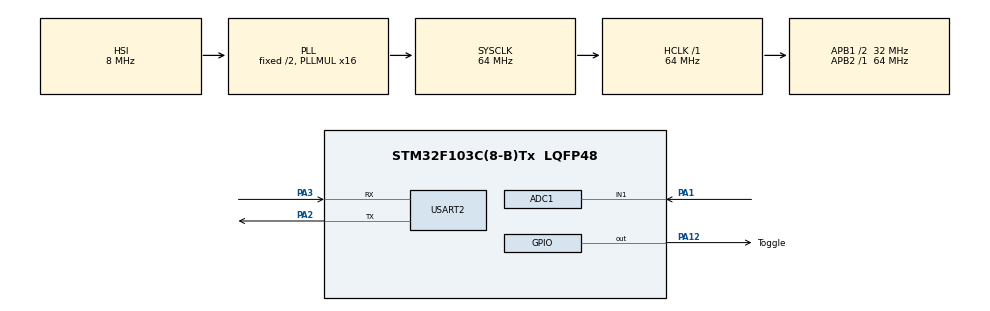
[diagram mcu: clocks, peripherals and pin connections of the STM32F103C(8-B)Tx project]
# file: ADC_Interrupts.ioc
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ADC1.Channel-0\#ChannelRegularConversion=ADC_CHANNEL_1
ADC1.ContinuousConvMode=ENABLE
ADC1.EnableAnalogWatchDog=false
ADC1.InjNumberOfConversion=0
ADC1.NbrOfConversion=1
ADC1.NbrOfConversionFlag=1
ADC1.Rank-0\#ChannelRegularConversion=1
ADC1.SamplingTime-0\#ChannelRegularConversion=ADC_SAMPLETIME_1CYCLE_5
ADC1.master=1
Mcu.Family=STM32F1
Mcu.Name=STM32F103C(8-B)Tx
Mcu.Package=LQFP48
NVIC.ADC1_2_IRQn=true\:0\:0\:false\:false\:true\:true\:true
NVIC.PriorityGroup=NVIC_PRIORITYGROUP_4
PA1.Signal=ADCx_IN1
PA12.GPIO_Label=Toggle
PA12.Signal=GPIO_Output
PA2.Mode=Asynchronous
PA2.Signal=USART2_TX
PA3.Mode=Asynchronous
PA3.Signal=USART2_RX
ProjectManager.HeapSize=0x200
ProjectManager.StackSize=0x400
ProjectManager.TargetToolchain=STM32CubeIDE
RCC.ADCPresc=RCC_ADCPCLK2_DIV6
RCC.AHBFreq_Value=64000000
RCC.APB1CLKDivider=RCC_HCLK_DIV2
RCC.APB1Freq_Value=32000000
RCC.APB1TimFreq_Value=64000000
RCC.APB2Freq_Value=64000000
RCC.APB2TimFreq_Value=64000000
RCC.HCLKFreq_Value=64000000
RCC.PLLMUL=RCC_PLL_MUL16
RCC.SYSCLKFreq_VALUE=64000000
RCC.SYSCLKSource=RCC_SYSCLKSOURCE_PLLCLK
RCC.USBFreq_Value=64000000
SH.ADCx_IN1.0=ADC1_IN1,IN1
USART2.Parity=PARITY_NONE
USART2.VirtualMode=VM_ASYNC
VP_SYS_VS_ND.Mode=No_Debug
board=custom

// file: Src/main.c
/* USER CODE BEGIN Header */
/**
  ******************************************************************************
  * @file           : main.c
  * @brief          : Main program body
  ******************************************************************************
  * @attention
  *
  * <h2><center>&copy; Copyright (c) 2019 STMicroelectronics.
  * All rights reserved.</center></h2>
  *
  * This software component is licensed by ST under BSD 3-Clause license,
  * the "License"; You may not use this file except in compliance with the
  * License. You may obtain a copy of the License at:
  *                        opensource.org/licenses/BSD-3-Clause
  *
  ******************************************************************************
  */
/* USER CODE END Header */

#include "main.h"

ADC_HandleTypeDef hadc1;

UART_HandleTypeDef huart2;

void SystemClock_Config(void);
static void MX_GPIO_Init(void);
static void MX_ADC1_Init(void);
static void MX_USART2_UART_Init(void);

int main(void)
{

  /* MCU Configuration--------------------------------------------------------*/

  /* Reset of all peripherals, Initializes the Flash interface and the Systick. */
  HAL_Init();

  /* Configure the system clock */
  SystemClock_Config();

  /* Initialize all configured peripherals */
  MX_GPIO_Init();
  MX_ADC1_Init();
  MX_USART2_UART_Init();
  /* USER CODE BEGIN 2 */

  HAL_UART_Transmit(&huart2, (uint8_t*) "begin\r\n", 7, HAL_MAX_DELAY);

  HAL_NVIC_SetPriority(ADC1_IRQn, 0, 0);
  HAL_NVIC_EnableIRQ(ADC1_IRQn);

  char msg[10];

  uint16_t aux = HAL_ADC_Start_IT(&hadc1);
  sprintf(msg, "%d\r\n", aux);
  HAL_UART_Transmit(&huart2, (uint8_t*) msg, 7, HAL_MAX_DELAY);
  /* USER CODE END 2 */

  /* Infinite loop */
  /* USER CODE BEGIN WHILE */
  while (1)
  {

	  //HAL_Delay(500);
	  //HAL_UART_Transmit(&huart2, (uint8_t*) "While Loop\r\n", 12, HAL_MAX_DELAY);

    /* USER CODE END WHILE */

  }
}

void SystemClock_Config(void)
{
  RCC_OscInitTypeDef RCC_OscInitStruct = {0};
  RCC_ClkInitTypeDef RCC_ClkInitStruct = {0};
  RCC_PeriphCLKInitTypeDef PeriphClkInit = {0};

  /** Initializes the CPU, AHB and APB busses clocks
  */
  RCC_OscInitStruct.OscillatorType = RCC_OSCILLATORTYPE_HSI;
  RCC_OscInitStruct.HSIState = RCC_HSI_ON;
  RCC_OscInitStruct.HSICalibrationValue = RCC_HSICALIBRATION_DEFAULT;
  RCC_OscInitStruct.PLL.PLLState = RCC_PLL_ON;
  RCC_OscInitStruct.PLL.PLLSource = RCC_PLLSOURCE_HSI_DIV2;
  RCC_OscInitStruct.PLL.PLLMUL = RCC_PLL_MUL16;
  if (HAL_RCC_OscConfig(&RCC_OscInitStruct) != HAL_OK)
  {
    Error_Handler();
  }
  /** Initializes the CPU, AHB and APB busses clocks
  */
  RCC_ClkInitStruct.ClockType = RCC_CLOCKTYPE_HCLK|RCC_CLOCKTYPE_SYSCLK
                              |RCC_CLOCKTYPE_PCLK1|RCC_CLOCKTYPE_PCLK2;
  RCC_ClkInitStruct.SYSCLKSource = RCC_SYSCLKSOURCE_PLLCLK;
  RCC_ClkInitStruct.AHBCLKDivider = RCC_SYSCLK_DIV1;
  RCC_ClkInitStruct.APB1CLKDivider = RCC_HCLK_DIV2;
  RCC_ClkInitStruct.APB2CLKDivider = RCC_HCLK_DIV1;

  if (HAL_RCC_ClockConfig(&RCC_ClkInitStruct, FLASH_LATENCY_2) != HAL_OK)
  {
    Error_Handler();
  }
  PeriphClkInit.PeriphClockSelection = RCC_PERIPHCLK_ADC;
  PeriphClkInit.AdcClockSelection = RCC_ADCPCLK2_DIV6;
  if (HAL_RCCEx_PeriphCLKConfig(&PeriphClkInit) != HAL_OK)
  {
    Error_Handler();
  }
}

static void MX_ADC1_Init(void)
{

  ADC_ChannelConfTypeDef sConfig = {0};

  /** Common config
  */
  hadc1.Instance = ADC1;
  hadc1.Init.ScanConvMode = ADC_SCAN_DISABLE;
  hadc1.Init.ContinuousConvMode = ENABLE;
  hadc1.Init.DiscontinuousConvMode = DISABLE;
  hadc1.Init.ExternalTrigConv = ADC_SOFTWARE_START;
  hadc1.Init.DataAlign = ADC_DATAALIGN_RIGHT;
  hadc1.Init.NbrOfConversion = 1;
  if (HAL_ADC_Init(&hadc1) != HAL_OK)
  {
    Error_Handler();
  }
  /** Configure Regular Channel
  */
  sConfig.Channel = ADC_CHANNEL_1;
  sConfig.Rank = ADC_REGULAR_RANK_1;
  sConfig.SamplingTime = ADC_SAMPLETIME_1CYCLE_5;
  if (HAL_ADC_ConfigChannel(&hadc1, &sConfig) != HAL_OK)
  {
    Error_Handler();
  }

}

static void MX_USART2_UART_Init(void)
{

  huart2.Instance = USART2;
  huart2.Init.BaudRate = 115200;
  huart2.Init.WordLength = UART_WORDLENGTH_8B;
  huart2.Init.StopBits = UART_STOPBITS_1;
  huart2.Init.Parity = UART_PARITY_NONE;
  huart2.Init.Mode = UART_MODE_TX_RX;
  huart2.Init.HwFlowCtl = UART_HWCONTROL_NONE;
  huart2.Init.OverSampling = UART_OVERSAMPLING_16;
  if (HAL_UART_Init(&huart2) != HAL_OK)
  {
    Error_Handler();
  }

}

static void MX_GPIO_Init(void)
{
  GPIO_InitTypeDef GPIO_InitStruct = {0};

  /* GPIO Ports Clock Enable */
  __HAL_RCC_GPIOA_CLK_ENABLE();

  /*Configure GPIO pin Output Level */
  HAL_GPIO_WritePin(Toggle_GPIO_Port, Toggle_Pin, GPIO_PIN_RESET);

  /*Configure GPIO pin : Toggle_Pin */
  GPIO_InitStruct.Pin = Toggle_Pin;
  GPIO_InitStruct.Mode = GPIO_MODE_OUTPUT_PP;
  GPIO_InitStruct.Pull = GPIO_NOPULL;
  GPIO_InitStruct.Speed = GPIO_SPEED_FREQ_LOW;
  HAL_GPIO_Init(Toggle_GPIO_Port, &GPIO_InitStruct);

}

/* USER CODE BEGIN 4 */

void ADC_IRQHandler(void) {

	//HAL_UART_Transmit(&huart2, (uint8_t*) "Handle\n", 7, HAL_MAX_DELAY);
	HAL_ADC_IRQHandler(&hadc1);
}

void HAL_ADC_ConvCpltCallback(ADC_HandleTypeDef* hadc) {

	//Frequencia = 189 kHz
	HAL_GPIO_TogglePin(GPIOA, Toggle_Pin);

}

/* USER CODE END 4 */

void Error_Handler(void)
{
  /* USER CODE BEGIN Error_Handler_Debug */
  /* User can add his own implementation to report the HAL error return state */
	HAL_UART_Transmit(&huart2, (uint8_t*) "Error\r\n", 7, HAL_MAX_DELAY);
	/* USER CODE END Error_Handler_Debug */
}

/************************ (C) COPYRIGHT STMicroelectronics *****END OF FILE****/
